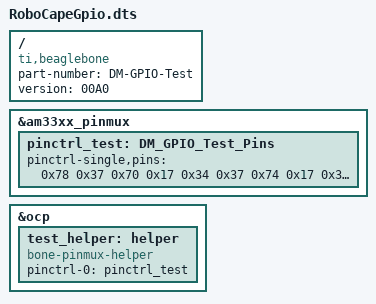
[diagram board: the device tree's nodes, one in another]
/*  
* Copyright (C) 2012 Texas Instruments Incorporated - http://www.ti.com/
*
* This program is free software; you can redistribute it and/or modify
* it under the terms of the GNU General Purpose License Version 2 as
* published by the Free Software Foundation
*
* Original from: github.com/jadonk/validation-scripts/blob/master/test-capemgr/ 
*
* Modified by Derek Molloy for the example on www.derekmolloy.ie
* that maps GPIO pins for the example
*/

/dts-v1/;
/plugin/;

/{
       compatible = "ti,beaglebone", "ti,beaglebone-black";
       part-number = "DM-GPIO-Test";
       version = "00A0";

       fragment@0 {
             target = <&am33xx_pinmux>;
            
             __overlay__ {
                  pinctrl_test: DM_GPIO_Test_Pins {
			pinctrl-single,pins = <

				/*0x078 0x07 */ /* P9_12 60 OUTPUT MODE7 - The LED Output */
				/*0x184 0x2f */ /* P9_24 15 INPUT  MODE7 none     - The Button Input */
				/*0x034 0x37*/  /* P8_11 45 INPUT  MODE7 pullup   - Yellow Wire */
				/*0x030 0x27 */ /* P8_12 44 INPUT  MODE7 pulldown - Green Wire */
				/*0x024 0x2f */ /* P8_13 23 INPUT  MODE7 none     - White Wire */
                       
        0x78  0x37	/* P9_12 60	 INPUT	 AdcStrbgpio INPUT  MODE7 pullup*/               
 		0x70  0x17	/* P9_11 30	 OUTPUT	 AdcCsngpio OUTPUT  MODE7 pullup*/
 		0x34  0x37	/* P8_11 45	 INPUT	 MotInt1gpio INPUT  MODE7 pullup*/
 		0x74  0x17	/* P9_13 31	 OUTPUT	 DigIOCsngpio OUTPUT  MODE7 pullup*/
 		0x30  0x17	/* P8_12 44	 OUTPUT	 StepClk0gpio OUTPUT MODE7*/
 		0x2c  0x17	/* P8_17 27	 OUTPUT	 StepClk1gpio OUTPUT MODE7*/
 		0x38  0x17	/* P8_16 46	 OUTPUT	 StepClk2gpio OUTPUT MODE7*/
 		0x7c  0x17	/* P8_26 61	 OUTPUT	 StepClk3gpio OUTPUT MODE7*/
 		0x164 0x37	/* P9_42 7 	 INPUT	 MotDir0gpio MODE7 pullup*/
 		0x28  0x37	/* P8_14 26	 INPUT	 MotDir1gpio MODE7 pullup*/
 		0x3c  0x37	/* P8_15 47	 INPUT	 MotDir2gpio MODE7 pullup*/
 		0x8c  0x37	/* P8_18 65	 INPUT 	 MotDir3gpio MODE7 pullup*/
 		0x40  0x17	/* P9_15 48	 OUTPUT	 SpiDevA0gpio OUTPUT MODE7*/
 		0x44  0x17	/* P9_23 49	 OUTPUT  SpiDevA1gpio OUTPUT MODE7*/
 		0x1a4 0x17	/* P9_27 115 OUTPUT	 SpiDevA2gpio OUTPUT MODE7*/
        0x1a0 0x37 	/* P9_42 114 INPUT	 GPIO318 MODE7 pullup*/ 
         	                    
                   /* OUTPUT  GPIO(mode7) 0x07 pulldown, 0x17 pullup, 0x?f no pullup/down */
			       /* INPUT   GPIO(mode7) 0x27 pulldown, 0x37 pullup, 0x?f no pullup/down */

			>;
		  };
             };
       };

       fragment@1 {
		target = <&ocp>;
		__overlay__ {
			test_helper: helper {
				compatible = "bone-pinmux-helper";
				pinctrl-names = "default";
				pinctrl-0 = <&pinctrl_test>;
				status = "okay";
			};
		};
	};
};

